# CTRL_MODULE_CORE register map
Vendor: Texas Instruments
Registers are 32-bit, access per field, reset 0x0 unless marked. A register's access mark holds for its fields unless they carry their own. Offsets are as the file gives them; [hi:lo] are bit positions; {n}, {i} and the like mark numbered series.

## CTRL_MODULE_CORE (part 3 of 5)
0x1014 CTRL_CORE_CONF_DEBUG_SEL_TST_2 — This register is used to select an observable signal for CORE observability line 2.
  [5:0] MODE rw — Selects one of the following signals to be available on CORE observability line 2. This signal can then be mapped to obs2 line throughCTRL_CORE_HWOBS_FINAL_MUX_SEL[2] bit. Values not shown are reserved.
    7=hwobs_debug_dss(2); 9=hwobs_dspdpll_tinitz; 11=hwobs_dsshdmiphypwrcmdtxon; 12=hwobs_ddrdpll_tinitz; 14=hwobs_emif1_pwr_sidleack(1); 18=hwobs_debug_debugss(2); 21=hwobs_emif1_phy_reg_status_dll_lock_byte0; 22=hwobs_emif1_phy_reg_rdlvl_dqs_ratio_byte0_rank0(2); 23=hwobs_emif1_phy_reg_rdlvl_dqs_ratio_byte0_rank1(2); 24=hwobs_emif1_phy_reg_status_phy_ctrl_dll_slave_value(0); 30=hwobs_eve1_eve_dbgout[21]; 34=hwobs_dsp1_Turing_hw_dbgout_[29]; 35=hwobs_dsp2_Turing_hw_dbgout_[29]; 38=hwobs_vip1_outmux_testport[2]; 42=hwobs_debug_prm(2); 43=hwobs_debug_cm_core_aon(2); 44=hwobs_int_iss(2); 45=hwobs_int_iss(34); 46=func_spare_out[2]; 47=dft_test_pad_i[2]; 48=dft_test_pad_o[2]
0x1018 CTRL_CORE_CONF_DEBUG_SEL_TST_3 — This register is used to select an observable signal for CORE observability line 3.
  [5:0] MODE rw — Selects one of the following signals to be available on CORE observability line 3. This signal can then be mapped to obs3 line throughCTRL_CORE_HWOBS_FINAL_MUX_SEL[3] bit. Values not shown are reserved.
    1=hwobs_coredpll_freqlock; 3=hwobs_dsi1adpll_freqlock; 7=hwobs_debug_dss(3); 9=hwobs_dspdpll_phaselock; 11=hwobs_dsshdmiphypwrcmdoff; 12=hwobs_ddrdpll_phaselock; 14=hwobs_emif1_pwr_sidleack(0); 18=hwobs_debug_debugss(3); 21=hwobs_emif1_phy_reg_rdfifo_rdptr_byte0(0); 22=hwobs_emif1_phy_reg_rdlvl_dqs_ratio_byte0_rank0(3); 23=hwobs_emif1_phy_reg_rdlvl_dqs_ratio_byte0_rank1(3); 24=hwobs_emif1_phy_reg_status_phy_ctrl_dll_slave_value(1); 30=hwobs_eve1_eve_dbgout[20]; 34=hwobs_dsp1_Turing_hw_dbgout_[28]; 35=hwobs_dsp2_Turing_hw_dbgout_[28]; 38=hwobs_vip1_outmux_testport[3]; 42=hwobs_debug_prm(3); 43=hwobs_debug_cm_core_aon(3); 44=hwobs_int_iss(3); 45=hwobs_int_iss(35); 46=func_spare_out[3]; 47=dft_test_pad_i[3]; 48=dft_test_pad_o[3]
0x101C CTRL_CORE_CONF_DEBUG_SEL_TST_4 — This register is used to select an observable signal for CORE observability line 4.
  [5:0] MODE rw — Selects one of the following signals to be available on CORE observability line 4. This signal can then be mapped to obs4 line throughCTRL_CORE_HWOBS_FINAL_MUX_SEL[4] bit. Values not shown are reserved.
    1=hwobs_coredpll_tinitz; 3=hwobs_dsi1adpll_tinitz; 7=hwobs_debug_dss(4); 9=hwobs_dspdpll_tenable; 11=hwobs_dsshdmiphypwrack; 12=hwobs_ddrdpll_tenable; 14=hwobs_emif1_pwr_fclken; 18=hwobs_debug_debugss(4); 21=hwobs_emif1_phy_reg_rdfifo_rdptr_byte0(1); 22=hwobs_emif1_phy_reg_rdlvl_dqs_ratio_byte0_rank0(4); 23=hwobs_emif1_phy_reg_rdlvl_dqs_ratio_byte0_rank1(4); 24=hwobs_emif1_phy_reg_status_phy_ctrl_dll_slave_value(2); 30=hwobs_eve1_eve_dbgout[19]; 34=hwobs_dsp1_Turing_hw_dbgout_[27]; 35=hwobs_dsp2_Turing_hw_dbgout_[27]; 38=hwobs_vip1_outmux_testport[4]; 42=hwobs_debug_prm(4); 43=hwobs_debug_cm_core_aon(4); 44=hwobs_int_iss(4); 45=hwobs_int_iss(36); 46=func_spare_out[4]; 47=dft_test_pad_i[4]; 48=dft_test_pad_o[4]
0x1020 CTRL_CORE_CONF_DEBUG_SEL_TST_5 — This register is used to select an observable signal for CORE observability line 5.
  [5:0] MODE rw — Selects one of the following signals to be available on CORE observability line 5. This signal can then be mapped to obs5 line throughCTRL_CORE_HWOBS_FINAL_MUX_SEL[5] bit. Values not shown are reserved.
    1=hwobs_coredpll_phaselock; 3=hwobs_dsi1adpll_phaselock; 7=hwobs_debug_dss(5); 9=hwobs_dspdpll_tenablediv; 11=hwobs_dsshdmihpd; 12=hwobs_ddrdpll_tenablediv; 14=hwobs_emif1_sys_err_intr_req; 18=hwobs_debug_debugss(5); 21=hwobs_emif1_phy_reg_rdfifo_rdptr_byte0(2); 22=hwobs_emif1_phy_reg_rdlvl_dqs_ratio_byte0_rank0(5); 23=hwobs_emif1_phy_reg_rdlvl_dqs_ratio_byte0_rank1(5); 24=hwobs_emif1_phy_reg_status_phy_ctrl_dll_slave_value(3); 30=hwobs_eve1_eve_dbgout[18]; 34=hwobs_dsp1_Turing_hw_dbgout_[26]; 35=hwobs_dsp2_Turing_hw_dbgout_[26]; 38=hwobs_vip1_outmux_testport[5]; 42=hwobs_debug_prm(5); 43=hwobs_debug_cm_core_aon(5); 44=hwobs_int_iss(5); 45=hwobs_int_iss(37); 46=func_spare_out[5]; 47=dft_test_pad_i[5]; 48=dft_test_pad_o[5]
0x1024 CTRL_CORE_CONF_DEBUG_SEL_TST_6 — This register is used to select an observable signal for CORE observability line 6.
  [5:0] MODE rw — Selects one of the following signals to be available on CORE observability line 6. This signal can then be mapped to obs6 line throughCTRL_CORE_HWOBS_FINAL_MUX_SEL[6] bit. Values not shown are reserved.
    1=hwobs_coredpll_tenable; 3=hwobs_dsi1adpll_tenable; 7=hwobs_debug_dss(6); 9=hwobs_dspdpll_bypassack; 11=hwobs_dssdsi1ascpenphy; 12=hwobs_ddrdpll_bypassack; 14=hwobs_emif1_sys_err_intr_pend; 18=hwobs_debug_debugss(6); 21=hwobs_emif1_phy_reg_rdfifo_wrptr_byte0(0); 22=hwobs_emif1_phy_reg_rdlvl_dqs_ratio_byte0_rank0(6); 23=hwobs_emif1_phy_reg_rdlvl_dqs_ratio_byte0_rank1(6); 24=hwobs_emif1_phy_reg_status_phy_ctrl_dll_slave_value(4); 30=hwobs_eve1_eve_dbgout[17]; 34=hwobs_dsp1_Turing_hw_dbgout_[25]; 35=hwobs_dsp2_Turing_hw_dbgout_[25]; 38=hwobs_vip1_outmux_testport[6]; 42=hwobs_debug_prm(6); 43=hwobs_debug_cm_core_aon(6); 44=hwobs_int_iss(6); 45=hwobs_int_iss(38); 46=func_spare_out[6]; 47=dft_test_pad_i[6]; 48=dft_test_pad_o[6]
0x1028 CTRL_CORE_CONF_DEBUG_SEL_TST_7 — This register is used to select an observable signal for CORE observability line 7.
  [5:0] MODE rw — Selects one of the following signals to be available on CORE observability line 7. This signal can then be mapped to obs7 line throughCTRL_CORE_HWOBS_FINAL_MUX_SEL[7] bit. Values not shown are reserved.
    1=hwobs_coredpll_tenablediv; 3=hwobs_dsi1adpll_tenablediv; 7=hwobs_debug_dss(7); 9=hwobs_dspdpll_idle; 11=hwobs_dssdsi1ascpaddr(3); 12=hwobs_ddrdpll_idle; 14=hwobs_emif1_ll_err_intr_req; 18=hwobs_debug_debugss(7); 21=hwobs_emif1_phy_reg_rdfifo_wrptr_byte0(1); 22=hwobs_emif1_phy_reg_rdlvl_dqs_ratio_byte0_rank0(7); 23=hwobs_emif1_phy_reg_rdlvl_dqs_ratio_byte0_rank1(7); 24=hwobs_emif1_phy_reg_status_phy_ctrl_dll_slave_value(5); 30=hwobs_eve1_eve_dbgout[16]; 34=hwobs_dsp1_Turing_hw_dbgout_[24]; 35=hwobs_dsp2_Turing_hw_dbgout_[24]; 38=hwobs_vip1_outmux_testport[7]; 42=hwobs_debug_prm(7); 43=hwobs_debug_cm_core_aon(7); 44=hwobs_int_iss(7); 45=hwobs_int_iss(39); 46=func_spare_out[7]; 47=dft_test_pad_i[7]; 48=dft_test_pad_o[7]
0x102C CTRL_CORE_CONF_DEBUG_SEL_TST_8 — This register is used to select an observable signal for CORE observability line 8.
  [5:0] MODE rw — Selects one of the following signals to be available on CORE observability line 8. This signal can then be mapped to obs8 line throughCTRL_CORE_HWOBS_FINAL_MUX_SEL[8] bit. Values not shown are reserved.
    1=hwobs_coredpll_bypassack; 3=hwobs_dsi1adpll_bypassack; 7=hwobs_debug_dss(8); 11=hwobs_dssdsi1ascpaddr(2); 12=hwobs_dsi1a_plllock; 14=hwobs_emif1_ll_err_intr_pend; 18=hwobs_debug_debugss(8); 21=hwobs_emif1_phy_reg_rdfifo_wrptr_byte0(2); 22=hwobs_emif1_phy_reg_rdlvl_dqs_ratio_byte0_rank0(8); 23=hwobs_emif1_phy_reg_rdlvl_dqs_ratio_byte0_rank1(8); 24=hwobs_emif1_phy_reg_status_phy_ctrl_dll_slave_value(6); 30=hwobs_eve1_eve_dbgout[15]; 34=hwobs_dsp1_Turing_hw_dbgout_[23]; 35=hwobs_dsp2_Turing_hw_dbgout_[23]; 38=hwobs_vip1_outmux_testport[8]; 42=hwobs_debug_prm(8); 43=hwobs_debug_cm_core_aon(8); 44=hwobs_int_iss(8); 45=hwobs_int_iss(40); 46=func_spare_out[8]; 47=dft_test_pad_i[8]; 48=dft_test_pad_o[8]
0x1030 CTRL_CORE_CONF_DEBUG_SEL_TST_9 — This register is used to select an observable signal for CORE observability line 9.
  [5:0] MODE rw — Selects one of the following signals to be available on CORE observability line 9. This signal can then be mapped to obs9 line throughCTRL_CORE_HWOBS_FINAL_MUX_SEL[9] bit. Values not shown are reserved.
    1=hwobs_coredpll_idle; 3=hwobs_dsi1adpll_idle; 7=hwobs_debug_dss(9); 9=hwobs_gmacdpll_freqlock; 11=hwobs_dssdsi1ascpaddr(1); 12=hwobs_dsi1a_pllrecal; 14=hwobs_emif1_ret_powerRet; 17=hwobs_mmc_adpidle; 18=hwobs_debug_debugss(9); 21=hwobs_emif1_phy_reg_gate_level_fsm_byte0(0); 22=hwobs_emif1_phy_reg_rdlvl_dqs_ratio_byte0_rank0(9); 23=hwobs_emif1_phy_reg_rdlvl_dqs_ratio_byte0_rank1(9); 24=hwobs_emif1_phy_reg_status_phy_ctrl_dll_slave_value(7); 30=hwobs_eve1_eve_dbgout[14]; 34=hwobs_dsp1_Turing_hw_dbgout_[22]; 35=hwobs_dsp2_Turing_hw_dbgout_[22]; 38=hwobs_vip1_outmux_testport[9]; 42=hwobs_debug_prm(9); 43=hwobs_debug_cm_core_aon(9); 44=hwobs_int_iss(9); 45=hwobs_int_iss(41); 46=func_spare_out[9]; 47=dft_test_pad_i[9]; 48=dft_test_pad_o[9]
0x1034 CTRL_CORE_CONF_DEBUG_SEL_TST_10 — This register is used to select an observable signal for CORE observability line 10.
  [5:0] MODE rw — Selects one of the following signals to be available on CORE observability line 10. This signal can then be mapped to obs10 line throughCTRL_CORE_HWOBS_FINAL_MUX_SEL[10] bit. Values not shown are reserved.
    1=hwobs_emif1_prcm_deviceoff_wkup_core_rstactst; 7=hwobs_debug_dss(10); 9=hwobs_gmacdpll_tinitz; 11=hwobs_dssdsi1ascpaddr(0); 12=hwobs_dsi1a_stopclock; 14=hwobs_emif1_phy_sdramclkstop_cmd(1); 17=hwobs_mmc_adpdat1paden; 18=hwobs_debug_debugss(10); 21=hwobs_emif1_phy_reg_gate_level_fsm_byte0(1); 22=hwobs_emif1_phy_reg_rdlvl_fifowein_ratio_byte0_rank0(0); 23=hwobs_emif1_phy_reg_rdlvl_fifowein_ratio_byte0_rank1(0); 24=hwobs_emif1_phy_reg_status_phy_ctrl_dll_slave_value(8); 30=hwobs_eve1_eve_dbgout[13]; 34=hwobs_dsp1_Turing_hw_dbgout_[21]; 35=hwobs_dsp2_Turing_hw_dbgout_[21]; 38=hwobs_vip1_outmux_testport[10]; 42=hwobs_debug_prm(10); 43=hwobs_debug_cm_core_aon(10); 44=hwobs_int_iss(10); 45=hwobs_int_iss(42); 46=func_spare_out[10]; 47=dft_test_pad_i[10]; 48=dft_test_pad_o[10]
0x1038 CTRL_CORE_CONF_DEBUG_SEL_TST_11 — This register is used to select an observable signal for CORE observability line 11.
  [5:0] MODE rw — Selects one of the following signals to be available on CORE observability line 11. This signal can then be mapped to obs11 line throughCTRL_CORE_HWOBS_FINAL_MUX_SEL[11] bit. Values not shown are reserved.
    1=hwobs_emif1_pwr_sidlereq; 7=hwobs_debug_dss(11); 9=hwobs_gmacdpll_phaselock; 11=hwobs_dssdsi1ascpcmd(1); 12=hwobs_dsi1a_stopclockackz; 14=hwobs_emif1_phy_sdramclkstop_cmd(0); 17=hwobs_mmc_ocpl4idlereq; 18=hwobs_debug_debugss(11); 21=hwobs_emif1_phy_reg_gate_level_fsm_byte0(2); 22=hwobs_emif1_phy_reg_rdlvl_fifowein_ratio_byte0_rank0(1); 23=hwobs_emif1_phy_reg_rdlvl_fifowein_ratio_byte0_rank1(1); 24=hwobs_emif1_phy_reg_status_phy_ctrl_dll_slave_value(9); 30=hwobs_eve1_eve_dbgout[12]; 34=hwobs_dsp1_Turing_hw_dbgout_[20]; 35=hwobs_dsp2_Turing_hw_dbgout_[20]; 38=hwobs_vip1_outmux_testport[11]; 42=hwobs_debug_prm(11); 43=hwobs_debug_cm_core_aon(11); 44=hwobs_int_iss(11); 45=hwobs_int_iss(43); 46=func_spare_out[11]; 47=dft_test_pad_i[11]; 48=dft_test_pad_o[11]
0x103C CTRL_CORE_CONF_DEBUG_SEL_TST_12 — This register is used to select an observable signal for CORE observability line 12.
  [5:0] MODE rw — Selects one of the following signals to be available on CORE observability line 12. This signal can then be mapped to obs12 line throughCTRL_CORE_HWOBS_FINAL_MUX_SEL[12] bit. Values not shown are reserved.
    1=hwobs_emif1_pwr_sidleack(1); 2=hwobs_coredivider_clkout3; 7=hwobs_debug_dss(12); 9=hwobs_gmacdpll_tenable; 11=hwobs_dssdsi1ascpcmd(0); 12=hwobs_dsi1a_dispcupdatesync; 17=hwobs_mmc_ocpl3mwait; 18=hwobs_debug_debugss(12); 21=hwobs_emif1_phy_reg_rd_level_fsm_byte0(0); 22=hwobs_emif1_phy_reg_rdlvl_fifowein_ratio_byte0_rank0(2); 23=hwobs_emif1_phy_reg_rdlvl_fifowein_ratio_byte0_rank1(2); 24=hwobs_emif1_phy_reg_status_phy_ctrl_dll_slave_value(10); 30=hwobs_eve1_eve_dbgout[11]; 34=hwobs_dsp1_Turing_hw_dbgout_[19]; 35=hwobs_dsp2_Turing_hw_dbgout_[19]; 38=hwobs_vip1_outmux_testport[12]; 42=hwobs_debug_prm(12); 43=hwobs_debug_cm_core_aon(12); 44=hwobs_int_iss(12); 45=hwobs_int_iss(44); 46=func_spare_out[12]; 47=dft_test_pad_i[12]; 48=dft_test_pad_o[12]
0x1040 CTRL_CORE_CONF_DEBUG_SEL_TST_13 — This register is used to select an observable signal for CORE observability line 13.
  [5:0] MODE rw — Selects one of the following signals to be available on CORE observability line 13. This signal can then be mapped to obs13 line throughCTRL_CORE_HWOBS_FINAL_MUX_SEL[13] bit. Values not shown are reserved.
    1=hwobs_emif1_pwr_sidleack(0); 2=hwobs_perdivider_clkout4; 7=hwobs_debug_dss(13); 9=hwobs_gmacdpll_tenablediv; 11=hwobs_dssdsi1cscpenphy; 12=hwobs_dsi1a_scpenpllctrl; 17=hwobs_mmc_pirffret; 18=hwobs_debug_debugss(13); 21=hwobs_emif1_phy_reg_rd_level_fsm_byte0(1); 22=hwobs_emif1_phy_reg_rdlvl_fifowein_ratio_byte0_rank0(3); 23=hwobs_emif1_phy_reg_rdlvl_fifowein_ratio_byte0_rank1(3); 24=hwobs_emif1_phy_reg_status_phy_ctrl_dll_slave_value(11); 30=hwobs_eve1_eve_dbgout[10]; 34=hwobs_dsp1_Turing_hw_dbgout_[18]; 35=hwobs_dsp2_Turing_hw_dbgout_[18]; 38=hwobs_vip1_outmux_testport[13]; 42=hwobs_debug_prm(13); 43=hwobs_debug_cm_core_aon(13); 44=hwobs_int_iss(13); 45=hwobs_int_iss(45); 46=func_spare_out[13]; 47=dft_test_pad_i[13]; 48=dft_test_pad_o[13]
0x1044 CTRL_CORE_CONF_DEBUG_SEL_TST_14 — This register is used to select an observable signal for CORE observability line 14.
  [5:0] MODE rw — Selects one of the following signals to be available on CORE observability line 14. This signal can then be mapped to obs14 line throughCTRL_CORE_HWOBS_FINAL_MUX_SEL[14] bit. Values not shown are reserved.
    1=hwobs_emif1_pwr_fclken; 7=hwobs_debug_dss(14); 9=hwobs_gmacdpll_bypassack; 11=hwobs_dssdsi1cscpaddr(3); 12=hwobs_dsi1a_scpcmd(1); 17=hwobs_mmc_ocpl4sidleacko(1); 18=hwobs_debug_debugss(14); 21=hwobs_emif1_phy_reg_rd_level_fsm_byte0(2); 22=hwobs_emif1_phy_reg_rdlvl_fifowein_ratio_byte0_rank0(4); 23=hwobs_emif1_phy_reg_rdlvl_fifowein_ratio_byte0_rank1(4); 24=hwobs_emif1_phy_reg_status_phy_ctrl_dll_slave_value(12); 30=hwobs_eve1_eve_dbgout[9]; 34=hwobs_dsp1_Turing_hw_dbgout_[17]; 35=hwobs_dsp2_Turing_hw_dbgout_[17]; 38=hwobs_vip1_outmux_testport[14]; 42=hwobs_debug_prm(14); 43=hwobs_debug_cm_core_aon(14); 44=hwobs_int_iss(14); 45=hwobs_int_iss(46); 46=func_spare_out[14]; 47=dft_test_pad_i[14]; 48=dft_test_pad_o[14]
0x1048 CTRL_CORE_CONF_DEBUG_SEL_TST_15 — This register is used to select an observable signal for CORE observability line 15.
  [5:0] MODE rw — Selects one of the following signals to be available on CORE observability line 15. This signal can then be mapped to obs15 line throughCTRL_CORE_HWOBS_FINAL_MUX_SEL[15] bit. Values not shown are reserved.
    1=hwobs_emif1_sys_err_intr_req; 7=hwobs_debug_dss(15); 9=hwobs_gmacdpll_idle; 11=hwobs_dssdsi1cscpaddr(2); 12=hwobs_dsi1a_scpcmd(0); 17=hwobs_mmc_ocpl4sidleacko(0); 18=hwobs_debug_debugss(15); 21=hwobs_emif1_phy_reg_rd_level_fsm_byte0(3); 22=hwobs_emif1_phy_reg_rdlvl_fifowein_ratio_byte0_rank0(5); 23=hwobs_emif1_phy_reg_rdlvl_fifowein_ratio_byte0_rank1(5); 24=hwobs_emif1_phy_reg_status_phy_ctrl_dll_slave_value(13); 30=hwobs_eve1_eve_dbgout[8]; 34=hwobs_dsp1_Turing_hw_dbgout_[16]; 35=hwobs_dsp2_Turing_hw_dbgout_[16]; 38=hwobs_vip1_outmux_testport[15]; 42=hwobs_debug_prm(15); 43=hwobs_debug_cm_core_aon(15); 44=hwobs_int_iss(15); 45=hwobs_int_iss(47); 46=func_spare_out[15]; 47=dft_test_pad_i[15]; 48=dft_test_pad_o[15]
0x104C CTRL_CORE_CONF_DEBUG_SEL_TST_16 — This register is used to select an observable signal for CORE observability line 16.
  [5:0] MODE rw — Selects one of the following signals to be available on CORE observability line 16. This signal can then be mapped to obs16 line throughCTRL_CORE_HWOBS_FINAL_MUX_SEL[16] bit. Values not shown are reserved.
    1=hwobs_emif1_sys_err_intr_pend; 7=hwobs_debug_dss(16); 11=hwobs_dssdsi1cscpaddr(1); 12=hwobs_dsi1a_scpaddr(3); 17=hwobs_mmc_ocpl3mstandbyo; 18=hwobs_debug_debugss(16); 21=hwobs_emif1_phy_reg_wr_level_fsm_byte0(0); 22=hwobs_emif1_phy_reg_rdlvl_fifowein_ratio_byte0_rank0(6); 23=hwobs_emif1_phy_reg_rdlvl_fifowein_ratio_byte0_rank1(6); 24=hwobs_emif1_phy_reg_status_phy_ctrl_dll_slave_value(14); 30=hwobs_eve1_eve_dbgout[7]; 34=hwobs_dsp1_Turing_hw_dbgout_[15]; 35=hwobs_dsp2_Turing_hw_dbgout_[15]; 38=hwobs_vip1_outmux_testport[16]; 42=hwobs_debug_prm(16); 43=hwobs_debug_cm_core_aon(16); 44=hwobs_int_iss(16); 45=hwobs_int_iss(48); 46=func_spare_out[16]; 47=dft_test_pad_i[16]; 48=dft_test_pad_o[16]
0x1050 CTRL_CORE_CONF_DEBUG_SEL_TST_17 — This register is used to select an observable signal for CORE observability line 17.
  [5:0] MODE rw — Selects one of the following signals to be available on CORE observability line 17. This signal can then be mapped to obs17 line throughCTRL_CORE_HWOBS_FINAL_MUX_SEL[17] bit. Values not shown are reserved.
    1=hwobs_emif1_ll_err_intr_req; 7=hwobs_debug_dss(17); 11=hwobs_dssdsi1cscpaddr(0); 12=hwobs_dsi1a_scpaddr(2); 17=hwobs_mmc_swakeup; 18=hwobs_debug_debugss(17); 21=hwobs_emif1_phy_reg_wr_level_fsm_byte0(1); 22=hwobs_emif1_phy_reg_rdlvl_fifowein_ratio_byte0_rank0(7); 23=hwobs_emif1_phy_reg_rdlvl_fifowein_ratio_byte0_rank1(7); 24=hwobs_emif1_phy_reg_status_phy_ctrl_dll_slave_value(15); 30=hwobs_eve1_eve_dbgout[6]; 34=hwobs_dsp1_Turing_hw_dbgout_[14]; 35=hwobs_dsp2_Turing_hw_dbgout_[14]; 38=hwobs_vip1_outmux_testport[17]; 42=hwobs_debug_prm(17); 43=hwobs_debug_cm_core_aon(17); 44=hwobs_int_iss(17); 45=hwobs_int_iss(49); 46=func_spare_out[17]; 47=dft_test_pad_i[17]; 48=dft_test_pad_o[17]
0x1054 CTRL_CORE_CONF_DEBUG_SEL_TST_18 — This register is used to select an observable signal for CORE observability line 18.
  [5:0] MODE rw — Selects one of the following signals to be available on CORE observability line 18. This signal can then be mapped to obs18 line throughCTRL_CORE_HWOBS_FINAL_MUX_SEL[18] bit. Values not shown are reserved.
    1=hwobs_emif1_ll_err_intr_pend; 7=hwobs_debug_dss(18); 11=hwobs_dssdsi1cscpcmd(1); 12=hwobs_dsi1a_scpaddr(1); 18=hwobs_debug_debugss(18); 21=hwobs_emif1_phy_reg_wr_level_fsm_byte0(2); 22=hwobs_emif1_phy_reg_rdlvl_fifowein_ratio_byte0_rank0(8); 23=hwobs_emif1_phy_reg_rdlvl_fifowein_ratio_byte0_rank1(8); 24=hwobs_emif1_phy_reg_status_phy_ctrl_dll_slave_value(16); 30=hwobs_eve1_eve_dbgout[5]; 34=hwobs_dsp1_Turing_hw_dbgout_[13]; 35=hwobs_dsp2_Turing_hw_dbgout_[13]; 38=hwobs_vip1_outmux_testport[18]; 42=hwobs_debug_prm(18); 43=hwobs_debug_cm_core_aon(18); 44=hwobs_int_iss(18); 45=hwobs_int_iss(50); 46=func_spare_out[18]; 47=dft_test_pad_i[18]; 48=dft_test_pad_o[18]
0x1058 CTRL_CORE_CONF_DEBUG_SEL_TST_19 — This register is used to select an observable signal for CORE observability line 19.
  [5:0] MODE rw — Selects one of the following signals to be available on CORE observability line 19. This signal can then be mapped to obs19 line throughCTRL_CORE_HWOBS_FINAL_MUX_SEL[19] bit. Values not shown are reserved.
    1=hwobs_emif1_ret_powerRet; 2=hwobs_perdpll_freqlock; 7=hwobs_debug_dss(19); 11=hwobs_dssdsi1cscpcmd(0); 12=hwobs_dsi1a_scpaddr(0); 18=hwobs_debug_debugss(19); 21=hwobs_emif1_phy_reg_status_dll_slave_value_byte0(0); 22=hwobs_emif1_phy_reg_rdlvl_fifowein_ratio_byte0_rank0(9); 23=hwobs_emif1_phy_reg_rdlvl_fifowein_ratio_byte0_rank1(9); 24=hwobs_emif1_phy_reg_status_phy_ctrl_dll_slave_value(17); 30=hwobs_eve1_eve_dbgout[4]; 34=hwobs_dsp1_Turing_hw_dbgout_[12]; 35=hwobs_dsp2_Turing_hw_dbgout_[12]; 38=hwobs_vip1_outmux_testport[19]; 42=hwobs_debug_prm(19); 43=hwobs_debug_cm_core_aon(19); 44=hwobs_int_iss(19); 45=hwobs_int_iss(51); 46=func_spare_out[19]; 47=dft_test_pad_i[19]; 48=dft_test_pad_o[19]
0x105C CTRL_CORE_CONF_DEBUG_SEL_TST_20 — This register is used to select an observable signal for CORE observability line 20.
  [5:0] MODE rw — Selects one of the following signals to be available on CORE observability line 20. This signal can then be mapped to obs20 line throughCTRL_CORE_HWOBS_FINAL_MUX_SEL[20] bit. Values not shown are reserved.
    1=hwobs_emif1_phy_sdramclkstop_cmd(0); 2=hwobs_perdpll_tinitz; 7=hwobs_debug_dss(20); 11=hwobs_dsshdmiscpaddr(3); 12=hwobs_dsi1a_scpout; 18=hwobs_debug_debugss(20); 21=hwobs_emif1_phy_reg_status_dll_slave_value_byte0(1); 22=hwobs_emif1_phy_reg_rdlvl_fifowein_ratio_byte0_rank0(10); 23=hwobs_emif1_phy_reg_rdlvl_fifowein_ratio_byte0_rank1(10); 24=hwobs_emif1_phy_dll_calib_cmd0; 30=hwobs_eve1_eve_dbgout[3]; 34=hwobs_dsp1_Turing_hw_dbgout_[11]; 35=hwobs_dsp2_Turing_hw_dbgout_[11]; 38=hwobs_vip1_outmux_testport[20]; 42=hwobs_debug_prm(20); 43=hwobs_debug_cm_core_aon(20); 44=hwobs_int_iss(20); 45=hwobs_int_iss(52); 46=func_spare_out[20]; 47=dft_test_pad_i[20]; 48=dft_test_pad_o[20]
0x1060 CTRL_CORE_CONF_DEBUG_SEL_TST_21 — This register is used to select an observable signal for CORE observability line 21.
  [5:0] MODE rw — Selects one of the following signals to be available on CORE observability line 21. This signal can then be mapped to obs21 line throughCTRL_CORE_HWOBS_FINAL_MUX_SEL[21] bit. Values not shown are reserved.
    2=hwobs_perdpll_phaselock; 7=hwobs_debug_dss(21); 11=hwobs_dsshdmiscpaddr(2); 12=hwobs_dsi1a_scpinpllctrl; 18=hwobs_debug_debugss(21); 21=hwobs_emif1_phy_reg_status_dll_slave_value_byte0(2); 22=hwobs_emif1_phy_reg_gate_level_fsm_byte0(0); 23=hwobs_emif1_phy_reg_wr_level_fsm_byte0(2); 24=hwobs_emif1_phy_dll_calib_cmd1; 30=hwobs_eve1_eve_dbgout[2]; 34=hwobs_dsp1_Turing_hw_dbgout_[10]; 35=hwobs_dsp2_Turing_hw_dbgout_[10]; 38=hwobs_vip1_outmux_testport[21]; 42=hwobs_debug_prm(21); 43=hwobs_debug_cm_core_aon(21); 44=hwobs_int_iss(21); 45=hwobs_int_iss(53); 46=func_spare_out[21]; 47=dft_test_pad_i[21]; 48=dft_test_pad_o[21]
0x1064 CTRL_CORE_CONF_DEBUG_SEL_TST_22 — This register is used to select an observable signal for CORE observability line 22.
  [5:0] MODE rw — Selects one of the following signals to be available on CORE observability line 22. This signal can then be mapped to obs22 line throughCTRL_CORE_HWOBS_FINAL_MUX_SEL[22] bit. Values not shown are reserved.
    2=hwobs_perdpll_tenable; 7=hwobs_debug_dss(22); 11=hwobs_dsshdmiscpaddr(1); 12=hwobs_dsi1a_scpbusy; 18=hwobs_debug_debugss(22); 21=hwobs_emif1_phy_reg_status_dll_slave_value_byte0(3); 22=hwobs_emif1_phy_reg_gate_level_fsm_byte0(1); 23=hwobs_emif1_phy_reg_wr_level_fsm_byte0(1); 30=hwobs_eve1_eve_dbgout[1]; 34=hwobs_dsp1_Turing_hw_dbgout_[9]; 35=hwobs_dsp2_Turing_hw_dbgout_[9]; 38=hwobs_vip1_outmux_testport[22]; 42=hwobs_debug_prm(22); 43=hwobs_debug_cm_core_aon(22); 44=hwobs_int_iss(22); 45=hwobs_int_iss(54); 46=func_spare_out[22]; 47=dft_test_pad_i[22]; 48=dft_test_pad_o[22]
0x1068 CTRL_CORE_CONF_DEBUG_SEL_TST_23 — This register is used to select an observable signal for CORE observability line 23.
  [5:0] MODE rw — Selects one of the following signals to be available on CORE observability line 23. This signal can then be mapped to obs23 line throughCTRL_CORE_HWOBS_FINAL_MUX_SEL[23] bit. Values not shown are reserved.
    2=hwobs_perdpll_tenablediv; 7=hwobs_debug_dss(23); 11=hwobs_dsshdmiscpaddr(0); 18=hwobs_debug_debugss(23); 21=hwobs_emif1_phy_reg_status_dll_slave_value_byte0(4); 22=hwobs_emif1_phy_reg_gate_level_fsm_byte0(2); 23=hwobs_emif1_phy_reg_wr_level_fsm_byte0(0); 30=hwobs_eve1_eve_dbgout[0]; 34=hwobs_dsp1_Turing_hw_dbgout_[8]; 35=hwobs_dsp2_Turing_hw_dbgout_[8]; 38=hwobs_vip1_outmux_testport[23]; 42=hwobs_debug_prm(23); 43=hwobs_debug_cm_core_aon(23); 44=hwobs_int_iss(23); 45=hwobs_int_iss(55); 46=func_spare_out[23]; 47=dft_test_pad_i[23]; 48=dft_test_pad_o[23]
0x106C CTRL_CORE_CONF_DEBUG_SEL_TST_24 — This register is used to select an observable signal for CORE observability line 24.
  [5:0] MODE rw — Selects one of the following signals to be available on CORE observability line 24. This signal can then be mapped to obs24 line throughCTRL_CORE_HWOBS_FINAL_MUX_SEL[24] bit. Values not shown are reserved.
    2=hwobs_perdpll_bypassack; 7=hwobs_debug_dss(24); 11=hwobs_dsshdmiscpcmd(1); 18=hwobs_debug_debugss(24); 21=hwobs_emif1_phy_reg_status_dll_slave_value_byte0(5); 22=hwobs_emif1_phy_reg_rd_level_fsm_byte0(0); 23=hwobs_emif1_phy_reg_rd_level_fsm_byte0(3); 34=hwobs_dsp1_Turing_hw_dbgout_[7]; 35=hwobs_dsp2_Turing_hw_dbgout_[7]; 38=hwobs_vip1_outmux_testport[24]; 42=hwobs_debug_prm(24); 43=hwobs_debug_cm_core_aon(24); 44=hwobs_int_iss(24); 45=hwobs_int_iss(56); 46=func_spare_out[24]; 47=dft_test_pad_i[24]; 48=dft_test_pad_o[24]
0x1070 CTRL_CORE_CONF_DEBUG_SEL_TST_25 — This register is used to select an observable signal for CORE observability line 25.
  [5:0] MODE rw — Selects one of the following signals to be available on CORE observability line 25. This signal can then be mapped to obs25 line throughCTRL_CORE_HWOBS_FINAL_MUX_SEL[25] bit. Values not shown are reserved.
    2=hwobs_perdpll_idle; 7=hwobs_debug_dss(25); 11=hwobs_dsshdmiscpcmd(0); 18=hwobs_debug_debugss(25); 21=hwobs_emif1_phy_reg_status_dll_slave_value_byte0(6); 22=hwobs_emif1_phy_reg_rd_level_fsm_byte0(1); 23=hwobs_emif1_phy_reg_rd_level_fsm_byte0(2); 34=hwobs_dsp1_Turing_hw_dbgout_[6]; 35=hwobs_dsp2_Turing_hw_dbgout_[6]; 38=hwobs_vip1_outmux_testport[25]; 42=hwobs_debug_prm(25); 43=hwobs_debug_cm_core_aon(25); 44=hwobs_int_iss(25); 46=func_spare_out[25]; 47=dft_test_pad_i[25]; 48=dft_test_pad_o[25]
0x1074 CTRL_CORE_CONF_DEBUG_SEL_TST_26 — This register is used to select an observable signal for CORE observability line 26.
  [5:0] MODE rw — Selects one of the following signals to be available on CORE observability line 26. This signal can then be mapped to obs26 line throughCTRL_CORE_HWOBS_FINAL_MUX_SEL[26] bit. Values not shown are reserved.
    7=hwobs_debug_dss(26); 18=hwobs_debug_debugss(26); 21=hwobs_emif1_phy_reg_status_dll_slave_value_byte0(7); 22=hwobs_emif1_phy_reg_rd_level_fsm_byte0(2); 23=hwobs_emif1_phy_reg_rd_level_fsm_byte0(1); 34=hwobs_dsp1_Turing_hw_dbgout_[5]; 35=hwobs_dsp2_Turing_hw_dbgout_[5]; 38=hwobs_vip1_outmux_testport[26]; 42=hwobs_debug_prm(26); 43=hwobs_debug_cm_core_aon(26); 44=hwobs_int_iss(26); 46=func_spare_out[26]; 47=dft_test_pad_i[26]; 48=dft_test_pad_o[26]
0x1078 CTRL_CORE_CONF_DEBUG_SEL_TST_27 — This register is used to select an observable signal for CORE observability line 27.
  [5:0] MODE rw — Selects one of the following signals to be available on CORE observability line 27. This signal can then be mapped to obs27 line throughCTRL_CORE_HWOBS_FINAL_MUX_SEL[27] bit. Values not shown are reserved.
    7=hwobs_debug_dss(27); 18=hwobs_debug_debugss(27); 21=hwobs_emif1_phy_reg_status_dll_slave_value_byte0(8); 22=hwobs_emif1_phy_reg_rd_level_fsm_byte0(3); 23=hwobs_emif1_phy_reg_rd_level_fsm_byte0(0); 34=hwobs_dsp1_Turing_hw_dbgout_[4]; 35=hwobs_dsp2_Turing_hw_dbgout_[4]; 38=hwobs_vip1_outmux_testport[27]; 42=hwobs_debug_prm(27); 43=hwobs_debug_cm_core_aon(27); 44=hwobs_int_iss(27); 46=func_spare_out[27]; 47=dft_test_pad_i[27]; 48=dft_test_pad_o[27]
0x107C CTRL_CORE_CONF_DEBUG_SEL_TST_28 — This register is used to select an observable signal for CORE observability line 28.
  [5:0] MODE rw — Selects one of the following signals to be available on CORE observability line 28. This signal can then be mapped to obs28 line throughCTRL_CORE_HWOBS_FINAL_MUX_SEL[28] bit. Values not shown are reserved.
    7=hwobs_debug_dss(28); 18=hwobs_debug_debugss(28); 21=hwobs_emif1_phy_dll_calib_data0; 22=hwobs_emif1_phy_reg_wr_level_fsm_byte0(0); 23=hwobs_emif1_phy_reg_gate_level_fsm_byte0(2); 34=hwobs_dsp1_Turing_hw_dbgout_[3]; 35=hwobs_dsp2_Turing_hw_dbgout_[3]; 38=hwobs_vip1_outmux_testport[28]; 42=hwobs_debug_prm(28); 43=hwobs_debug_cm_core_aon(28); 44=hwobs_int_iss(28); 46=func_spare_out[28]; 47=dft_test_pad_i[28]; 48=dft_test_pad_o[28]
0x1080 CTRL_CORE_CONF_DEBUG_SEL_TST_29 — This register is used to select an observable signal for CORE observability line 29.
  [5:0] MODE rw — Selects one of the following signals to be available on CORE observability line 29. This signal can then be mapped to obs29 line throughCTRL_CORE_HWOBS_FINAL_MUX_SEL[29] bit. Values not shown are reserved.
    7=hwobs_debug_dss(29); 18=hwobs_debug_debugss(29); 21=hwobs_emif1_pwrdn_dq0; 22=hwobs_emif1_phy_reg_wr_level_fsm_byte0(1); 23=hwobs_emif1_phy_reg_gate_level_fsm_byte0(1); 34=hwobs_dsp1_Turing_hw_dbgout_[2]; 35=hwobs_dsp2_Turing_hw_dbgout_[2]; 38=hwobs_vip1_outmux_testport[29]; 42=hwobs_debug_prm(29); 43=hwobs_debug_cm_core_aon(29); 44=hwobs_int_iss(29); 46=func_spare_out[29]; 47=dft_test_pad_i[29]; 48=dft_test_pad_o[29]
0x1084 CTRL_CORE_CONF_DEBUG_SEL_TST_30 — This register is used to select an observable signal for CORE observability line 30.
  [5:0] MODE rw — Selects one of the following signals to be available on CORE observability line 30. This signal can then be mapped to obs30 line throughCTRL_CORE_HWOBS_FINAL_MUX_SEL[30] bit. Values not shown are reserved.
    2=hwobs_emif1_phy_sdramclkstop_cmd(1); 7=hwobs_debug_dss(30); 18=hwobs_debug_debugss(30); 22=hwobs_emif1_phy_reg_wr_level_fsm_byte0(2); 23=hwobs_emif1_phy_reg_gate_level_fsm_byte0(0); 34=hwobs_dsp1_Turing_hw_dbgout_[1]; 35=hwobs_dsp2_Turing_hw_dbgout_[1]; 38=hwobs_vip1_outmux_testport[30]; 42=hwobs_debug_prm(30); 43=hwobs_debug_cm_core_aon(30); 44=hwobs_int_iss(30); 46=func_spare_out[30]; 47=dft_test_pad_i[30]; 48=dft_test_pad_o[30]
0x1088 CTRL_CORE_CONF_DEBUG_SEL_TST_31 — This register is used to select an observable signal for CORE observability line 31.
  [5:0] MODE rw — Selects one of the following signals to be available on CORE observability line 31. This signal can then be mapped to obs31 line throughCTRL_CORE_HWOBS_FINAL_MUX_SEL[31] bit. Values not shown are reserved.
    7=hwobs_debug_dss(31); 18=hwobs_debug_debugss(31); 34=hwobs_dsp1_Turing_hw_dbgout_[0]; 35=hwobs_dsp2_Turing_hw_dbgout_[0]; 38=hwobs_vip1_outmux_testport[31]; 42=hwobs_debug_prm(31); 43=hwobs_debug_cm_core_aon(31); 44=hwobs_int_iss(31); 46=func_spare_out[31]; 47=dft_test_pad_i[31]; 48=dft_test_pad_o[31]
{0x100C+4i} CTRL_CORE_CONF_DEBUG_SEL_TST_{i} (i=32..47) — This register is used to select a signal for observation using line {i-32} of the system event detection bus which is part of the device OCP-WP.
  [2:0] MODE rw — Selects one of the following signals to be available on line {i-32} of the system event detection bus. Values not shown are reserved.
    4=hwobs_debug_cm_core_aon({i-32}); 5=hwobs_debug_cm_core_aon({i-16})
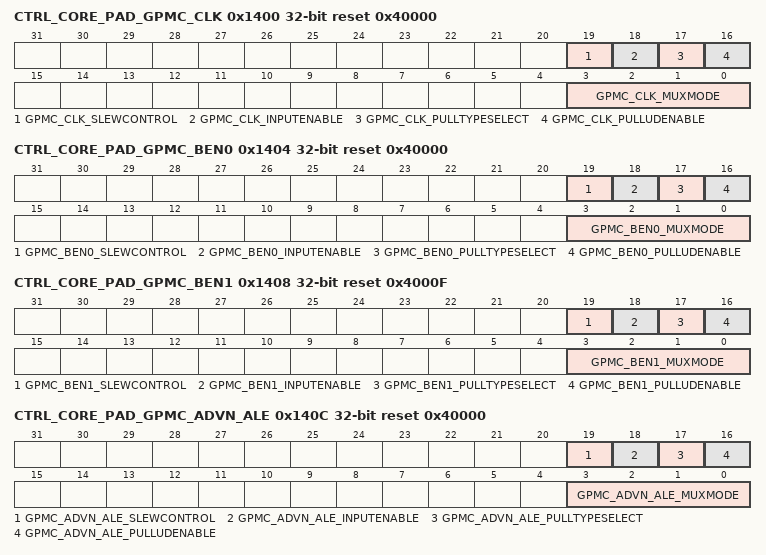
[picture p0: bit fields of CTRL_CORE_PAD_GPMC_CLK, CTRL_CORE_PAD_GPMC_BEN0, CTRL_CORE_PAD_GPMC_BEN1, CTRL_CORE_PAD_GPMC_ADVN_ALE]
0x1400 CTRL_CORE_PAD_GPMC_CLK reset 0x40000
  [19] GPMC_CLK_SLEWCONTROL rw
    0=Fast_slew_is_selected; 1=Slow_slew_is_selected
  [18] GPMC_CLK_INPUTENABLE rw
    0=Receive_mode_is_disabled; 1=Receive_mode_is_enabled
  [17] GPMC_CLK_PULLTYPESELECT rw
    0=Pull_Down_is_selected; 1=Pull_Up_is_selected
  [16] GPMC_CLK_PULLUDENABLE rw
    0=Enables_weak_Pull_Up/Down; 1=Disables_weak_Pull_Up/Down
  [3:0] GPMC_CLK_MUXMODE rw
    0=GPMC_CLK; 1=RGMII1_TXC; 5=CLKOUT0; 6=DMA_EVT1; 14=GPIO1_0; 15=DRIVER_OFF
0x1404 CTRL_CORE_PAD_GPMC_BEN0 reset 0x40000
  [19] GPMC_BEN0_SLEWCONTROL rw
    0=Fast_slew_is_selected; 1=Slow_slew_is_selected
  [18] GPMC_BEN0_INPUTENABLE rw
    0=Receive_mode_is_disabled; 1=Receive_mode_is_enabled
  [17] GPMC_BEN0_PULLTYPESELECT rw
    0=Pull_Down_is_selected; 1=Pull_Up_is_selected
  [16] GPMC_BEN0_PULLUDENABLE rw
    0=Enables_weak_Pull_Up/Down; 1=Disables_weak_Pull_Up/Down
  [3:0] GPMC_BEN0_MUXMODE rw
    0=GPMC_BEN0; 1=RGMII1_TXCTL; 4=EHRPWM1A; 6=DMA_EVT2; 14=GPIO1_1; 15=DRIVER_OFF
0x1408 CTRL_CORE_PAD_GPMC_BEN1 reset 0x4000F
  [19] GPMC_BEN1_SLEWCONTROL rw
    0=Fast_slew_is_selected; 1=Slow_slew_is_selected
  [18] GPMC_BEN1_INPUTENABLE rw
    0=Receive_mode_is_disabled; 1=Receive_mode_is_enabled
  [17] GPMC_BEN1_PULLTYPESELECT rw
    0=Pull_Down_is_selected; 1=Pull_Up_is_selected
  [16] GPMC_BEN1_PULLUDENABLE rw
    0=Enables_weak_Pull_Up/Down; 1=Disables_weak_Pull_Up/Down
  [3:0] GPMC_BEN1_MUXMODE rw
    0=GPMC_BEN1; 1=RGMII1_TXD3; 4=EHRPWM1B; 6=DMA_EVT3; 14=GPIO1_2; 15=DRIVER_OFF
0x140C CTRL_CORE_PAD_GPMC_ADVN_ALE reset 0x40000
  [19] GPMC_ADVN_ALE_SLEWCONTROL rw
    0=Fast_slew_is_selected; 1=Slow_slew_is_selected
  [18] GPMC_ADVN_ALE_INPUTENABLE rw
    0=Receive_mode_is_disabled; 1=Receive_mode_is_enabled
  [17] GPMC_ADVN_ALE_PULLTYPESELECT rw
    0=Pull_Down_is_selected; 1=Pull_Up_is_selected
  [16] GPMC_ADVN_ALE_PULLUDENABLE rw
    0=Enables_weak_Pull_Up/Down; 1=Disables_weak_Pull_Up/Down
  [3:0] GPMC_ADVN_ALE_MUXMODE rw
    0=GPMC_ADVN_ALE; 1=RGMII1_TXD2; 4=EHRPWM1_TRIPZONE_INPUT; 5=CLKOUT1; 6=DMA_EVT4; 14=GPIO1_3; 15=DRIVER_OFF
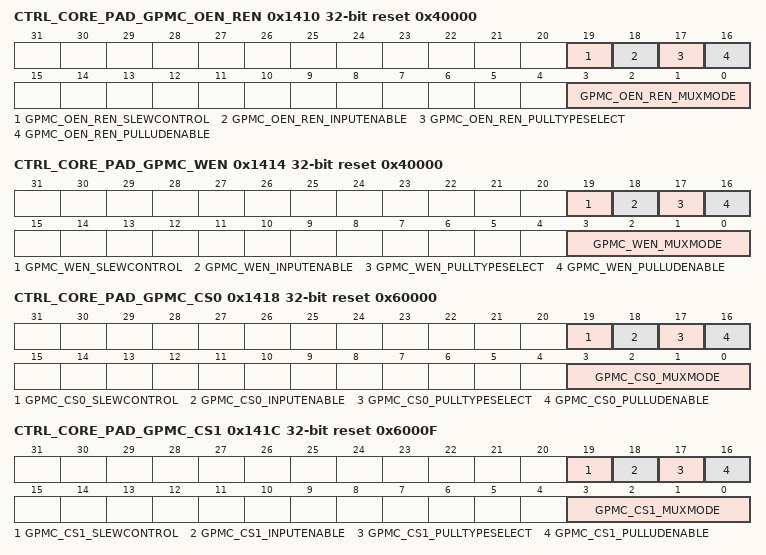
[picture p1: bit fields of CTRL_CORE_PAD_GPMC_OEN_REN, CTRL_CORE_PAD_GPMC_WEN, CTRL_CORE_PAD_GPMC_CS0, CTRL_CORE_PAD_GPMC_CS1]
0x1410 CTRL_CORE_PAD_GPMC_OEN_REN reset 0x40000
  [19] GPMC_OEN_REN_SLEWCONTROL rw
    0=Fast_slew_is_selected; 1=Slow_slew_is_selected
  [18] GPMC_OEN_REN_INPUTENABLE rw
    0=Receive_mode_is_disabled; 1=Receive_mode_is_enabled
  [17] GPMC_OEN_REN_PULLTYPESELECT rw
    0=Pull_Down_is_selected; 1=Pull_Up_is_selected
  [16] GPMC_OEN_REN_PULLUDENABLE rw
    0=Enables_weak_Pull_Up/Down; 1=Disables_weak_Pull_Up/Down
  [3:0] GPMC_OEN_REN_MUXMODE rw
    0=GPMC_OEN_REN; 1=RGMII1_TXD1; 4=EHRPWM1_SYNCI; 5=CLKOUT2; 14=GPIO1_4; 15=DRIVER_OFF
0x1414 CTRL_CORE_PAD_GPMC_WEN reset 0x40000
  [19] GPMC_WEN_SLEWCONTROL rw
    0=Fast_slew_is_selected; 1=Slow_slew_is_selected
  [18] GPMC_WEN_INPUTENABLE rw
    0=Receive_mode_is_disabled; 1=Receive_mode_is_enabled
  [17] GPMC_WEN_PULLTYPESELECT rw
    0=Pull_Down_is_selected; 1=Pull_Up_is_selected
  [16] GPMC_WEN_PULLUDENABLE rw
    0=Enables_weak_Pull_Up/Down; 1=Disables_weak_Pull_Up/Down
  [3:0] GPMC_WEN_MUXMODE rw
    0=GPMC_WEN; 1=RGMII1_TXD0; 4=EHRPWM1_SYNCO; 14=GPIO1_5; 15=DRIVER_OFF
0x1418 CTRL_CORE_PAD_GPMC_CS0 reset 0x60000
  [19] GPMC_CS0_SLEWCONTROL rw
    0=Fast_slew_is_selected; 1=Slow_slew_is_selected
  [18] GPMC_CS0_INPUTENABLE rw
    0=Receive_mode_is_disabled; 1=Receive_mode_is_enabled
  [17] GPMC_CS0_PULLTYPESELECT rw
    0=Pull_Down_is_selected; 1=Pull_Up_is_selected
  [16] GPMC_CS0_PULLUDENABLE rw
    0=Enables_weak_Pull_Up/Down; 1=Disables_weak_Pull_Up/Down
  [3:0] GPMC_CS0_MUXMODE rw
    0=GPMC_CS0; 1=RGMII1_RXCTL; 14=GPIO1_6; 15=DRIVER_OFF
0x141C CTRL_CORE_PAD_GPMC_CS1 reset 0x6000F
  [19] GPMC_CS1_SLEWCONTROL rw
    0=Fast_slew_is_selected; 1=Slow_slew_is_selected
  [18] GPMC_CS1_INPUTENABLE rw
    0=Receive_mode_is_disabled; 1=Receive_mode_is_enabled
  [17] GPMC_CS1_PULLTYPESELECT rw
    0=Pull_Down_is_selected; 1=Pull_Up_is_selected
  [16] GPMC_CS1_PULLUDENABLE rw
    0=Enables_weak_Pull_Up/Down; 1=Disables_weak_Pull_Up/Down
  [3:0] GPMC_CS1_MUXMODE rw
    0=GPMC_CS1; 1=QSPI1_CS0; 14=GPIO1_7; 15=DRIVER_OFF
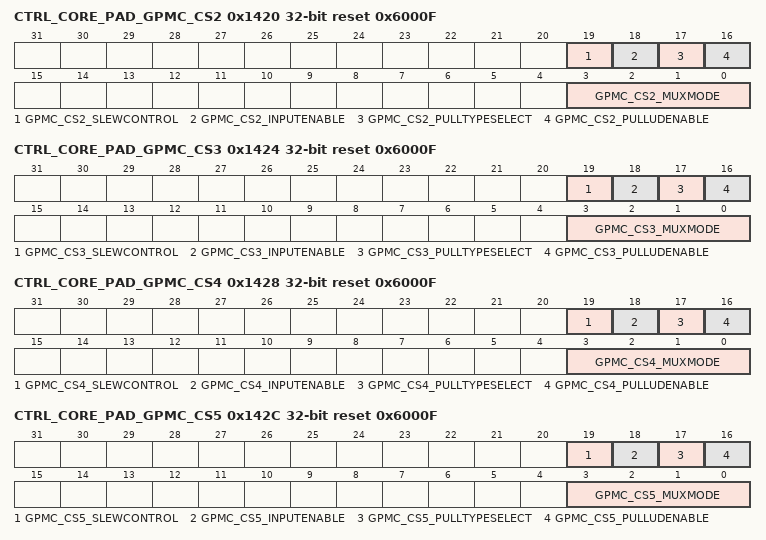
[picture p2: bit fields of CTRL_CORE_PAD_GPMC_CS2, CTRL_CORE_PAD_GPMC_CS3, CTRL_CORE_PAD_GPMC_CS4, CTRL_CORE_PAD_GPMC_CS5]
0x1420 CTRL_CORE_PAD_GPMC_CS2 reset 0x6000F
  [19] GPMC_CS2_SLEWCONTROL rw
    0=Fast_slew_is_selected; 1=Slow_slew_is_selected
  [18] GPMC_CS2_INPUTENABLE rw
    0=Receive_mode_is_disabled; 1=Receive_mode_is_enabled
  [17] GPMC_CS2_PULLTYPESELECT rw
    0=Pull_Down_is_selected; 1=Pull_Up_is_selected
  [16] GPMC_CS2_PULLUDENABLE rw
    0=Enables_weak_Pull_Up/Down; 1=Disables_weak_Pull_Up/Down
  [3:0] GPMC_CS2_MUXMODE rw
    0=GPMC_CS2; 1=QSPI1_D3; 14=GPIO1_8; 15=DRIVER_OFF
0x1424 CTRL_CORE_PAD_GPMC_CS3 reset 0x6000F
  [19] GPMC_CS3_SLEWCONTROL rw
    0=Fast_slew_is_selected; 1=Slow_slew_is_selected
  [18] GPMC_CS3_INPUTENABLE rw
    0=Receive_mode_is_disabled; 1=Receive_mode_is_enabled
  [17] GPMC_CS3_PULLTYPESELECT rw
    0=Pull_Down_is_selected; 1=Pull_Up_is_selected
  [16] GPMC_CS3_PULLUDENABLE rw
    0=Enables_weak_Pull_Up/Down; 1=Disables_weak_Pull_Up/Down
  [3:0] GPMC_CS3_MUXMODE rw
    0=GPMC_CS3; 1=QSPI1_D2; 14=GPIO1_9; 15=DRIVER_OFF
0x1428 CTRL_CORE_PAD_GPMC_CS4 reset 0x6000F
  [19] GPMC_CS4_SLEWCONTROL rw
    0=Fast_slew_is_selected; 1=Slow_slew_is_selected
  [18] GPMC_CS4_INPUTENABLE rw
    0=Receive_mode_is_disabled; 1=Receive_mode_is_enabled
  [17] GPMC_CS4_PULLTYPESELECT rw
    0=Pull_Down_is_selected; 1=Pull_Up_is_selected
  [16] GPMC_CS4_PULLUDENABLE rw
    0=Enables_weak_Pull_Up/Down; 1=Disables_weak_Pull_Up/Down
  [3:0] GPMC_CS4_MUXMODE rw
    0=GPMC_CS4; 1=QSPI1_D0; 14=GPIO1_10; 15=DRIVER_OFF
0x142C CTRL_CORE_PAD_GPMC_CS5 reset 0x6000F
  [19] GPMC_CS5_SLEWCONTROL rw
    0=Fast_slew_is_selected; 1=Slow_slew_is_selected
  [18] GPMC_CS5_INPUTENABLE rw
    0=Receive_mode_is_disabled; 1=Receive_mode_is_enabled
  [17] GPMC_CS5_PULLTYPESELECT rw
    0=Pull_Down_is_selected; 1=Pull_Up_is_selected
  [16] GPMC_CS5_PULLUDENABLE rw
    0=Enables_weak_Pull_Up/Down; 1=Disables_weak_Pull_Up/Down
  [3:0] GPMC_CS5_MUXMODE rw
    0=GPMC_CS5; 1=QSPI1_D1; 14=GPIO1_11; 15=DRIVER_OFF
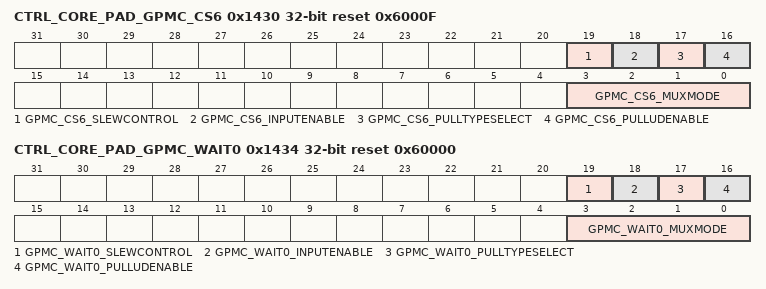
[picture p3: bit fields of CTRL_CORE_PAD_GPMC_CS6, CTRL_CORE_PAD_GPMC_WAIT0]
0x1430 CTRL_CORE_PAD_GPMC_CS6 reset 0x6000F
  [19] GPMC_CS6_SLEWCONTROL rw
    0=Fast_slew_is_selected; 1=Slow_slew_is_selected
  [18] GPMC_CS6_INPUTENABLE rw
    0=Receive_mode_is_disabled; 1=Receive_mode_is_enabled
  [17] GPMC_CS6_PULLTYPESELECT rw
    0=Pull_Down_is_selected; 1=Pull_Up_is_selected
  [16] GPMC_CS6_PULLUDENABLE rw
    0=Enables_weak_Pull_Up/Down; 1=Disables_weak_Pull_Up/Down
  [3:0] GPMC_CS6_MUXMODE rw
    0=GPMC_CS6; 1=QSPI1_SCLK; 14=GPIO1_12; 15=DRIVER_OFF
0x1434 CTRL_CORE_PAD_GPMC_WAIT0 reset 0x60000
  [19] GPMC_WAIT0_SLEWCONTROL rw
    0=Fast_slew_is_selected; 1=Slow_slew_is_selected
  [18] GPMC_WAIT0_INPUTENABLE rw
    0=Receive_mode_is_disabled; 1=Receive_mode_is_enabled
  [17] GPMC_WAIT0_PULLTYPESELECT rw
    0=Pull_Down_is_selected; 1=Pull_Up_is_selected
  [16] GPMC_WAIT0_PULLUDENABLE rw
    0=Enables_weak_Pull_Up/Down; 1=Disables_weak_Pull_Up/Down
  [3:0] GPMC_WAIT0_MUXMODE rw
    0=GPMC_WAIT0; 1=RGMII1_RXD3; 2=QSPI1_RTCLK; 6=DMA_EVT4; 14=GPIO1_13; 15=DRIVER_OFF
